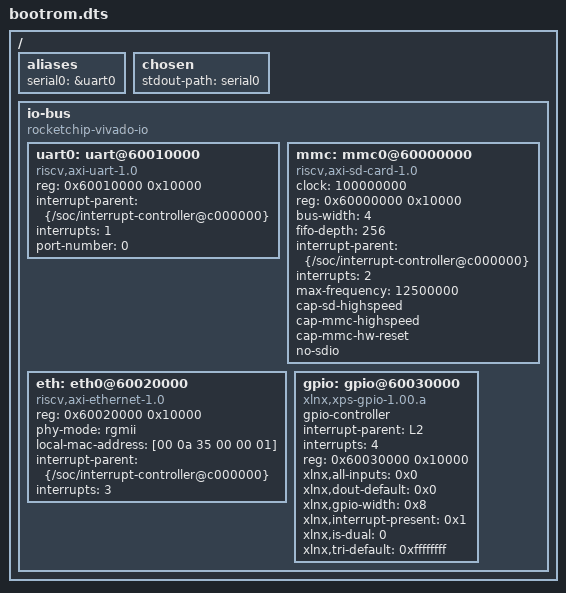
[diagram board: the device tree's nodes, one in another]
/ {

    aliases {
        serial0 = &uart0;
    };

    chosen {
        stdout-path = "serial0";
    };

    io-bus {
        #address-cells = <1>;
        #size-cells = <1>;
        compatible = "rocketchip-vivado-io", "simple-bus";
        ranges;

        uart0: uart@60010000 {
            compatible = "riscv,axi-uart-1.0";
            reg = <0x60010000 0x10000>;
            interrupt-parent = <&{/soc/interrupt-controller@c000000}>;
            interrupts = <1>;
            port-number = <0>;
        };

        mmc: mmc0@60000000 {
            compatible = "riscv,axi-sd-card-1.0";
            clock = <100000000>;
            reg = <0x60000000 0x10000>;
            bus-width = <4>;
            fifo-depth = <256>;
            interrupt-parent = <&{/soc/interrupt-controller@c000000}>;
            interrupts = <2>;
            max-frequency = <12500000>;
            cap-sd-highspeed;
            cap-mmc-highspeed;
            cap-mmc-hw-reset;
            no-sdio;
        };

        eth: eth0@60020000 {
            compatible = "riscv,axi-ethernet-1.0";
            reg = <0x60020000 0x10000>;
            phy-mode = "rgmii";
            local-mac-address = [00 0a 35 00 00 01];
            interrupt-parent = <&{/soc/interrupt-controller@c000000}>;
            interrupts = <3>;
        };

        gpio: gpio@60030000 {
            #gpio-cells = <2>;
            compatible = "xlnx,xps-gpio-1.00.a";
            gpio-controller ;vi
            interrupt-parent = <&L2>;
            interrupts = <4>;
            reg = < 0x60030000 0x10000 >;
            xlnx,all-inputs = <0x0>;
            xlnx,dout-default = <0x0>;
            xlnx,gpio-width = <0x8>;
            xlnx,interrupt-present = <0x1>;
            xlnx,is-dual = <0>;
            xlnx,tri-default = <0xffffffff>;
        };

    };
};
